# WKUP_VTM0_MMR_VBUSP_CFG2 register map
Vendor: Texas Instruments
Peripheral module from a debugger description file (folder J7ES).
Registers are 32-bit, read-write, reset 0x0 unless marked. A register's access mark holds for its fields unless they carry their own. Offsets are as the file gives them; lines under a group give offsets from that group; [hi:lo] are bit positions; {n}, {i} and the like mark numbered series; 'fields as' and 'values as' point back to an identical list; <NAME> marks a mode.

## WKUP_VTM0_MMR_VBUSP_CFG2
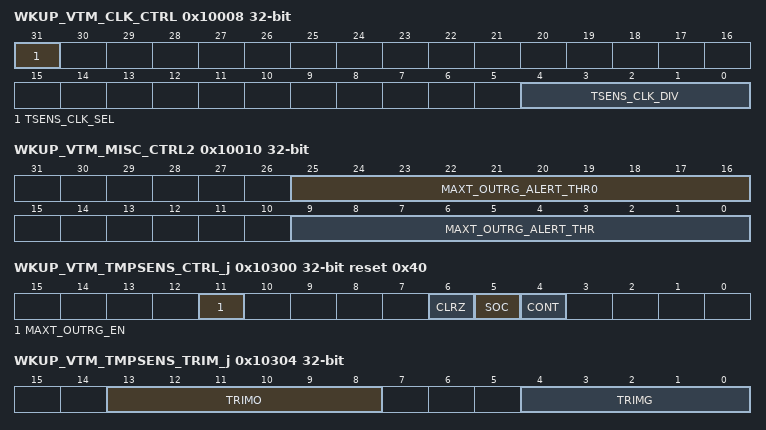
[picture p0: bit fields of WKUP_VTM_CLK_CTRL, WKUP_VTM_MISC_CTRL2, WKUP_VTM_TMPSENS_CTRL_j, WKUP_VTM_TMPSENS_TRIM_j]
0x10008 WKUP_VTM_CLK_CTRL — VTM clock related control MMR. The default reset values will not be necessarily overwritten. The write capability in the MMR is for having the option to debug and have software driven adjustments if necessary. The e-fuse value is sampled from input port efuse_tsens_clk_src_div. The tsens_clks_src_div field is Device specific.
  [31] TSENS_CLK_SEL — Temperature sensor clock source selector.
  [4:0] TSENS_CLK_DIV — Temperature sensor clock source divider selector.
0x1000C WKUP_VTM_MISC_CTRL — VTM miscellaneous control bits.
  [0] ANY_MAXT_OUTRG_ALERT_EN — This bit when enabled will cause the VTM's output therm_maxtemp_outrange_alert to be driven high, if any of the sources for the maxt_outrg_alert, is set high.
0x10010 WKUP_VTM_MISC_CTRL2 — VTM miscellaneous control bits.
  [25:16] MAXT_OUTRG_ALERT_THR0 — This defines the global max temperature out of range safe sample value.
  [9:0] MAXT_OUTRG_ALERT_THR — This defines the global max temperature out of range sample value.
0x10020 WKUP_VTM_SAMPLE_CTRL — VTM sample related control MMR. The default reset values will not be necessarily overwritten. The write capability in the MMR is for having the option to debug and have software driven adjustments if necessary. The e-fuse value is sampled from input port efuse_sample_clk_cnt. The sample_clk_cnt field is Device specific.
  [15:0] SAMPLE_PER_CNT — Temperature sensor sample period count selector.
0x10300 WKUP_VTM_TMPSENS_CTRL_j reset 0x40 — Temperature Sensor Band-gap control register for sensor a. Offset = 300h + (j * 20h); where j = 0h to 7h
  [11] MAXT_OUTRG_EN — Enable out-of-range event.
  [6] CLRZ — Temp-Monitor control:
  [5] SOC — Temp-Monitor control: ADC Start of Conversion.
  [4] CONT — Temp-Monitor control: ADC Continuous mode.
0x10304 WKUP_VTM_TMPSENS_TRIM_j reset not defined — Temperature Sensor Band-gap trim values register for sensor a. The default reset values will not be necessarily overwritten. The write capability in the MMR is for having the option to debug and have software driven adjustments if necessary. Offset = 304h + (j * 20h); where j = 0h to 7h
  [13:8] TRIMO — Trim offset bits in the temp sensor.
  [4:0] TRIMG — Trim gain bits in the temp sensor.
